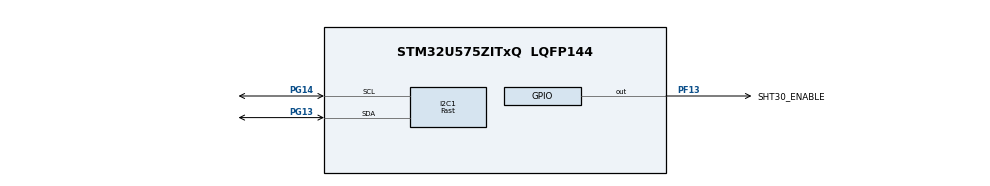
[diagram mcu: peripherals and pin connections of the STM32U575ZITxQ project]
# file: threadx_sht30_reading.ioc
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CORTEX_M33_NS.userName=CORTEX_M33
I2C1.I2C_Speed_Mode=I2C_Fast
I2C1.Timing=0x00000004
Mcu.Family=STM32U5
Mcu.Name=STM32U575ZITxQ
Mcu.Package=LQFP144
NVIC.PriorityGroup=NVIC_PRIORITYGROUP_4
NVIC.TIM6_IRQn=true\:15\:0\:false\:false\:true\:false\:false\:true\:true
NVIC.TimeBase=TIM6_IRQn
NVIC.TimeBaseIP=TIM6
PF13.GPIO_Label=SHT30_ENABLE
PF13.GPIO_PuPd=GPIO_NOPULL
PF13.Signal=GPIO_Output
PG13.Mode=I2C
PG13.Signal=I2C1_SDA
PG14.Mode=I2C
PG14.Signal=I2C1_SCL
ProjectManager.HeapSize=0x200
ProjectManager.StackSize=0x400
ProjectManager.TargetToolchain=STM32CubeIDE
RCC.ADCFreq_Value=16000000
RCC.DACCLockSelectionVirtualString=RCC_DAC1CLKSOURCE_LSI
RCC.EPOD_VALUE=4000000
RCC.HSE_VALUE=16000000
RCC.HSI48_VALUE=48000000
RCC.HSI_VALUE=16000000
RCC.LSE_VALUE=32768
RCC.LSIDIV_VALUE=32000
RCC.MSI_VALUE=4000000
RCC.USBFreq_Value=48000000
RCC.VCOOutputFreq_Value=516000000
VP_SYS_VS_tim6.Mode=TIM6
VP_THREADX_VS_RTOSJjThreadXJjCoreJjDefault.Mode=Core_Default
board=custom

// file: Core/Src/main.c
/* USER CODE BEGIN Header */
/**
  ******************************************************************************
  * @file           : main.c
  * @brief          : Main program body
  ******************************************************************************
  * @attention
  *
  * Copyright (c) 2023 STMicroelectronics.
  * All rights reserved.
  *
  * This software is licensed under terms that can be found in the LICENSE file
  * in the root directory of this software component.
  * If no LICENSE file comes with this software, it is provided AS-IS.
  *
  ******************************************************************************
  */
/* USER CODE END Header */
#include "main.h"
#include "app_threadx.h"

/* USER CODE BEGIN Includes */
#include "sht3x.h"
/* USER CODE END Includes */

I2C_HandleTypeDef hi2c1;

/* USER CODE BEGIN PV */
float temperature, humidity;
/* USER CODE END PV */

void SystemClock_Config(void);
static void SystemPower_Config(void);
static void MX_GPIO_Init(void);
static void MX_I2C1_Init(void);
/* USER CODE BEGIN PFP */
void SHT30_Initialization(void);	// definition of SHT30 Initialization Function
void SHT30_Pin_Reset(void); 			// definition of SHT30 Reset Function
/* USER CODE END PFP */

int main(void)
{

  /* MCU Configuration--------------------------------------------------------*/

  /* Reset of all peripherals, Initializes the Flash interface and the Systick. */
  HAL_Init();

  /* Configure the system clock */
  SystemClock_Config();

  /* Configure the System Power */
  SystemPower_Config();

  /* Initialize all configured peripherals */
  MX_GPIO_Init();
  MX_I2C1_Init();
  /* USER CODE BEGIN 2 */
  SHT30_Initialization();
  /* USER CODE END 2 */

  MX_ThreadX_Init();

  /* We should never get here as control is now taken by the scheduler */
  /* Infinite loop */
  while (1)
  {

  }
}

void SystemClock_Config(void)
{
  RCC_OscInitTypeDef RCC_OscInitStruct = {0};
  RCC_ClkInitTypeDef RCC_ClkInitStruct = {0};

  /** Configure the main internal regulator output voltage
  */
  if (HAL_PWREx_ControlVoltageScaling(PWR_REGULATOR_VOLTAGE_SCALE4) != HAL_OK)
  {
    Error_Handler();
  }

  /** Initializes the CPU, AHB and APB buses clocks
  */
  RCC_OscInitStruct.OscillatorType = RCC_OSCILLATORTYPE_MSI;
  RCC_OscInitStruct.MSIState = RCC_MSI_ON;
  RCC_OscInitStruct.MSICalibrationValue = RCC_MSICALIBRATION_DEFAULT;
  RCC_OscInitStruct.MSIClockRange = RCC_MSIRANGE_4;
  RCC_OscInitStruct.PLL.PLLState = RCC_PLL_NONE;
  if (HAL_RCC_OscConfig(&RCC_OscInitStruct) != HAL_OK)
  {
    Error_Handler();
  }

  /** Initializes the CPU, AHB and APB buses clocks
  */
  RCC_ClkInitStruct.ClockType = RCC_CLOCKTYPE_HCLK|RCC_CLOCKTYPE_SYSCLK
                              |RCC_CLOCKTYPE_PCLK1|RCC_CLOCKTYPE_PCLK2
                              |RCC_CLOCKTYPE_PCLK3;
  RCC_ClkInitStruct.SYSCLKSource = RCC_SYSCLKSOURCE_MSI;
  RCC_ClkInitStruct.AHBCLKDivider = RCC_SYSCLK_DIV1;
  RCC_ClkInitStruct.APB1CLKDivider = RCC_HCLK_DIV1;
  RCC_ClkInitStruct.APB2CLKDivider = RCC_HCLK_DIV1;
  RCC_ClkInitStruct.APB3CLKDivider = RCC_HCLK_DIV1;

  if (HAL_RCC_ClockConfig(&RCC_ClkInitStruct, FLASH_LATENCY_0) != HAL_OK)
  {
    Error_Handler();
  }
}

/**
  * @brief Power Configuration
  * @retval None
  */
static void SystemPower_Config(void)
{
  HAL_PWREx_EnableVddIO2();

}

static void MX_I2C1_Init(void)
{

  hi2c1.Instance = I2C1;
  hi2c1.Init.Timing = 0x00000004;
  hi2c1.Init.OwnAddress1 = 0;
  hi2c1.Init.AddressingMode = I2C_ADDRESSINGMODE_7BIT;
  hi2c1.Init.DualAddressMode = I2C_DUALADDRESS_DISABLE;
  hi2c1.Init.OwnAddress2 = 0;
  hi2c1.Init.OwnAddress2Masks = I2C_OA2_NOMASK;
  hi2c1.Init.GeneralCallMode = I2C_GENERALCALL_DISABLE;
  hi2c1.Init.NoStretchMode = I2C_NOSTRETCH_DISABLE;
  if (HAL_I2C_Init(&hi2c1) != HAL_OK)
  {
    Error_Handler();
  }

  /** Configure Analogue filter
  */
  if (HAL_I2CEx_ConfigAnalogFilter(&hi2c1, I2C_ANALOGFILTER_ENABLE) != HAL_OK)
  {
    Error_Handler();
  }

  /** Configure Digital filter
  */
  if (HAL_I2CEx_ConfigDigitalFilter(&hi2c1, 0) != HAL_OK)
  {
    Error_Handler();
  }

}

static void MX_GPIO_Init(void)
{
  GPIO_InitTypeDef GPIO_InitStruct = {0};

  /* GPIO Ports Clock Enable */
  __HAL_RCC_GPIOF_CLK_ENABLE();
  __HAL_RCC_GPIOG_CLK_ENABLE();

  /*Configure GPIO pin Output Level */
  HAL_GPIO_WritePin(SHT30_ENABLE_GPIO_Port, SHT30_ENABLE_Pin, GPIO_PIN_RESET);

  /*Configure GPIO pin : SHT30_ENABLE_Pin */
  GPIO_InitStruct.Pin = SHT30_ENABLE_Pin;
  GPIO_InitStruct.Mode = GPIO_MODE_OUTPUT_PP;
  GPIO_InitStruct.Pull = GPIO_NOPULL;
  GPIO_InitStruct.Speed = GPIO_SPEED_FREQ_LOW;
  HAL_GPIO_Init(SHT30_ENABLE_GPIO_Port, &GPIO_InitStruct);

}

/* USER CODE BEGIN 4 */
void SHT30_Initialization(void)
{
	/**
	 * @note   This function initializes SHT30 sensor.
	 */

	SHT30_Pin_Reset(); // Restart SHT30.
	sht3x_handle_t handle = { .i2c_handle = &hi2c1,
			.device_address = SHT3X_I2C_DEVICE_ADDRESS_ADDR_PIN_LOW }; // Define i2c channel and SHT30 sensor's i2c address.
	sht3x_init(&handle); // Run SHT30's library's initialize function with using defined parameters.
}

void SHT30_Pin_Reset(void)
{
	/**
	  * @note   This function restarts SHT30 sensor by it's 6th pin.
	  */

	HAL_GPIO_WritePin(SHT30_ENABLE_GPIO_Port, SHT30_ENABLE_Pin, GPIO_PIN_RESET);	// SHT30 nReset Pin LOW
	HAL_Delay(100);																	// delay for 100 milliseconds
	HAL_GPIO_WritePin(SHT30_ENABLE_GPIO_Port, SHT30_ENABLE_Pin, GPIO_PIN_SET);		// SHT30 nReset Pin HIGH
	HAL_Delay(100);																	// delay for 100 milliseconds
}
/* USER CODE END 4 */

void HAL_TIM_PeriodElapsedCallback(TIM_HandleTypeDef *htim)
{
  if (htim->Instance == TIM6) {
    HAL_IncTick();
  }
}

void Error_Handler(void)
{
  __disable_irq();
  while (1)
  {
  }
}
